VERSION ""

NS_ :

BS_:

BU_: Motor_Controller

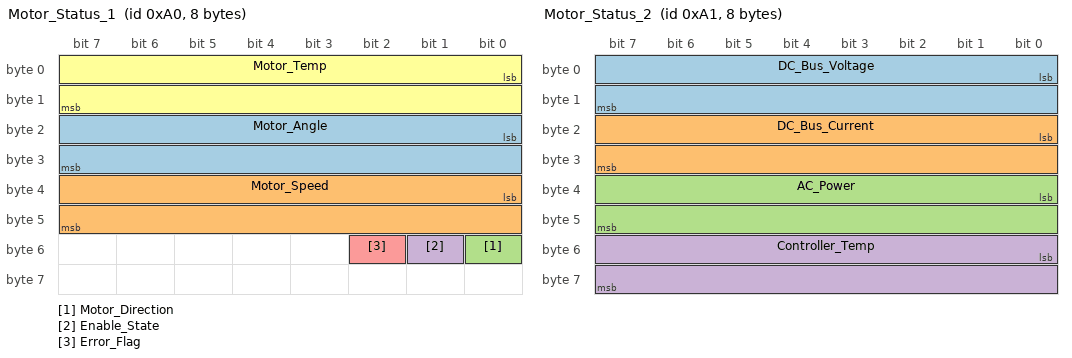
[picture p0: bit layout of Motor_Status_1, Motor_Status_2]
BO_ 160 Motor_Status_1: 8 Motor_Controller
 SG_ Motor_Angle : 16|16@1+ (0.1,0) [0|6553.5] "deg" Vector__XXX
 SG_ Motor_Speed : 32|16@1+ (1,0) [-32768|32767] "rpm" Vector__XXX
 SG_ Motor_Direction : 48|1@1+ (1,0) [0|1] "" Vector__XXX
 SG_ Enable_State : 49|1@1+ (1,0) [0|1] "" Vector__XXX
 SG_ Error_Flag : 50|1@1+ (1,0) [0|1] "" Vector__XXX
 SG_ Motor_Temp : 0|16@1+ (0.1,-40) [-40|6513.5] "degC" Vector__XXX

BO_ 161 Motor_Status_2: 8 Motor_Controller
 SG_ DC_Bus_Voltage : 0|16@1+ (0.1,0) [0|6553.5] "V" Vector__XXX
 SG_ DC_Bus_Current : 16|16@1+ (0.1,-3276.8) [-3276.8|3276.7] "A" Vector__XXX
 SG_ AC_Power : 32|16@1+ (0.25,0) [0|16383.75] "kW" Vector__XXX
 SG_ Controller_Temp : 48|16@1+ (0.1,-40) [-40|6513.5] "degC" Vector__XXX

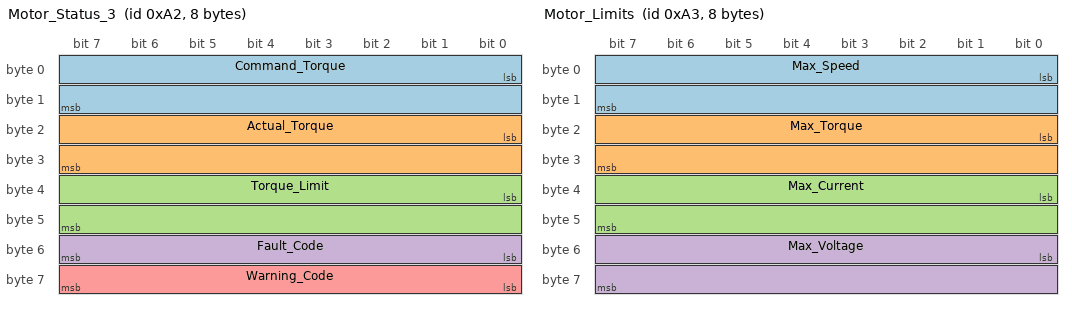
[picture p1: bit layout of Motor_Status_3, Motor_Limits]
BO_ 162 Motor_Status_3: 8 Motor_Controller
 SG_ Command_Torque : 0|16@1+ (0.1,-3276.8) [-3276.8|3276.7] "Nm" Vector__XXX
 SG_ Actual_Torque : 16|16@1+ (0.1,-3276.8) [-3276.8|3276.7] "Nm" Vector__XXX
 SG_ Torque_Limit : 32|16@1+ (0.1,0) [0|6553.5] "Nm" Vector__XXX
 SG_ Fault_Code : 48|8@1+ (1,0) [0|255] "" Vector__XXX
 SG_ Warning_Code : 56|8@1+ (1,0) [0|255] "" Vector__XXX

BO_ 163 Motor_Limits: 8 Motor_Controller
 SG_ Max_Speed : 0|16@1+ (1,0) [0|65535] "rpm" Vector__XXX
 SG_ Max_Torque : 16|16@1+ (0.1,0) [0|6553.5] "Nm" Vector__XXX
 SG_ Max_Current : 32|16@1+ (0.1,0) [0|6553.5] "A" Vector__XXX
 SG_ Max_Voltage : 48|16@1+ (0.1,0) [0|6553.5] "V" Vector__XXX

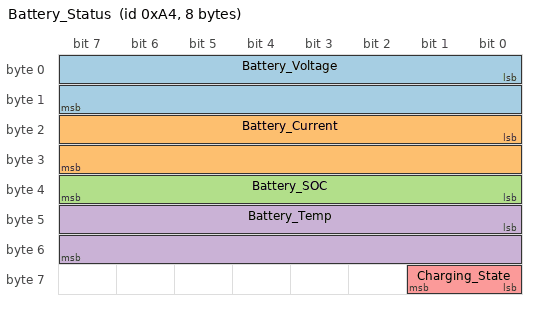
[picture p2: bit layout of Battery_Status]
BO_ 164 Battery_Status: 8 Motor_Controller
 SG_ Battery_Voltage : 0|16@1+ (0.01,0) [0|655.35] "V" Vector__XXX
 SG_ Battery_Current : 16|16@1+ (0.1,-3276.8) [-3276.8|3276.7] "A" Vector__XXX
 SG_ Battery_SOC : 32|8@1+ (0.5,0) [0|100] "%" Vector__XXX
 SG_ Battery_Temp : 40|16@1+ (0.1,-40) [-40|6513.5] "degC" Vector__XXX
 SG_ Charging_State : 56|2@1+ (1,0) [0|3] "" Vector__XXX

CM_ BO_ 160 "Primary motor status message containing angle, speed, and basic status";
CM_ BO_ 161 "DC bus parameters and AC power output";
CM_ BO_ 162 "Torque command, feedback, and fault information";
CM_ BO_ 163 "Motor operational limits";
CM_ BO_ 164 "Battery pack status and charging information";

CM_ SG_ 160 Motor_Direction "0=Forward, 1=Reverse";
CM_ SG_ 160 Enable_State "0=Disabled, 1=Enabled";
CM_ SG_ 160 Error_Flag "0=No Error, 1=Error Present";
CM_ SG_ 164 Charging_State "0=Not Charging, 1=Charging, 2=Charged, 3=Error";

VAL_ 160 Motor_Direction 0 "Forward" 1 "Reverse";
VAL_ 160 Enable_State 0 "Disabled" 1 "Enabled";
VAL_ 160 Error_Flag 0 "No Error" 1 "Error";
VAL_ 164 Charging_State 0 "Not Charging" 1 "Charging" 2 "Charged" 3 "Error";

BA_DEF_  "BusType" STRING ;
BA_DEF_ BO_  "GenMsgCycleTime" INT 0 3600000;

BA_ "BusType" "CAN";
BA_ "GenMsgCycleTime" BO_ 160 100;
BA_ "GenMsgCycleTime" BO_ 161 100;
BA_ "GenMsgCycleTime" BO_ 162 100;
BA_ "GenMsgCycleTime" BO_ 163 1000;
BA_ "GenMsgCycleTime" BO_ 164 500;
